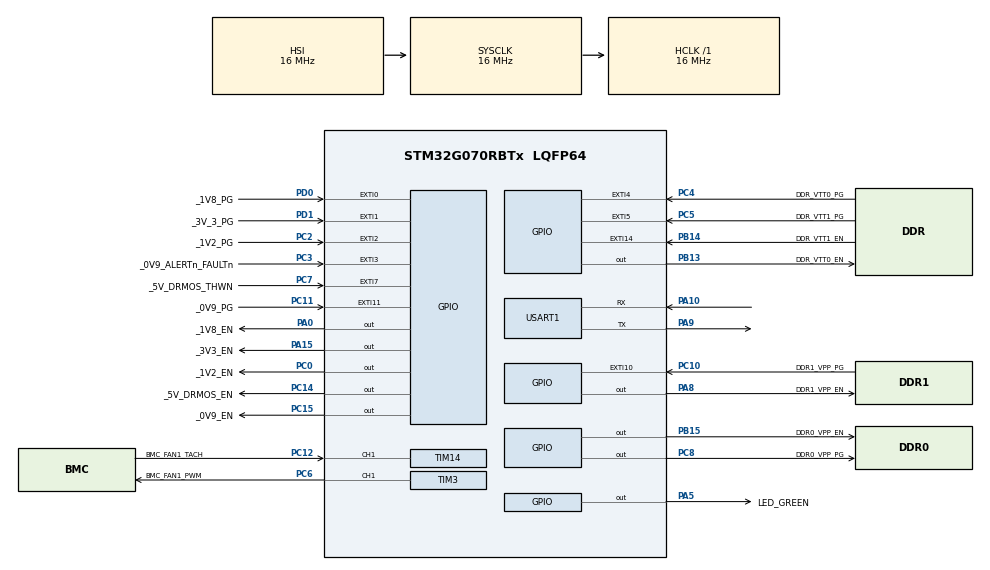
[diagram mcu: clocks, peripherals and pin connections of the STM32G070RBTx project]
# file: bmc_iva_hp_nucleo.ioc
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Mcu.Family=STM32G0
Mcu.Name=STM32G070RBTx
Mcu.Package=LQFP64
PA0.GPIO_Label=_1V8_EN
PA0.Signal=GPIO_Output
PA10.Mode=Asynchronous
PA10.Signal=USART1_RX
PA13.GPIO_Label=TMS
PA13.Mode=Serial_Wire
PA13.Signal=SYS_SWDIO
PA14-BOOT0.GPIO_Label=TCK
PA14-BOOT0.Mode=Serial_Wire
PA14-BOOT0.Signal=SYS_SWCLK
PA15.GPIO_Label=_3V3_EN
PA15.Signal=GPIO_Output
PA2.GPIO_PuPd=GPIO_PULLUP
PA2.Signal=USART2_TX
PA3.GPIO_PuPd=GPIO_PULLUP
PA3.Signal=USART2_RX
PA5.GPIO_Label=LED_GREEN
PA5.GPIO_Speed=GPIO_SPEED_FREQ_HIGH
PA5.Signal=GPIO_Output
PA8.GPIO_Label=DDR1_VPP_EN
PA8.Signal=GPIO_Output
PA9.Mode=Asynchronous
PA9.Signal=USART1_TX
PB13.GPIO_Label=DDR_VTT0_EN
PB13.Signal=GPIO_Output
PB14.GPIO_Label=DDR_VTT1_EN
PB14.Signal=GPXTI14
PB15.GPIO_Label=DDR0_VPP_EN
PB15.Signal=GPIO_Output
PC0.GPIO_Label=_1V2_EN
PC0.Signal=GPIO_Output
PC10.GPIO_Label=DDR1_VPP_PG
PC10.GPIO_ModeDefaultEXTI=GPIO_MODE_IT_RISING_FALLING
PC10.Signal=GPXTI10
PC11.GPIO_Label=_0V9_PG
PC11.GPIO_ModeDefaultEXTI=GPIO_MODE_IT_RISING_FALLING
PC11.Signal=GPXTI11
PC12.GPIO_Label=BMC_FAN1_TACH
PC12.Signal=S_TIM14_CH1
PC13.Mode=SYS_WakeUp1
PC13.Signal=SYS_WKUP2
PC14-OSC32_IN\ (PC14).GPIO_Label=_5V_DRMOS_EN
PC14-OSC32_IN\ (PC14).Signal=GPIO_Output
PC15-OSC32_OUT\ (PC15).GPIO_Label=_0V9_EN
PC15-OSC32_OUT\ (PC15).Signal=GPIO_Output
PC2.GPIO_Label=_1V2_PG
PC2.GPIO_ModeDefaultEXTI=GPIO_MODE_IT_RISING_FALLING
PC2.Signal=GPXTI2
PC3.GPIO_Label=_0V9_ALERTn_FAULTn
PC3.GPIO_ModeDefaultEXTI=GPIO_MODE_IT_RISING_FALLING
PC3.Signal=GPXTI3
PC4.GPIO_Label=DDR_VTT0_PG
PC4.GPIO_ModeDefaultEXTI=GPIO_MODE_IT_RISING_FALLING
PC4.Signal=GPXTI4
PC5.GPIO_Label=DDR_VTT1_PG
PC5.GPIO_ModeDefaultEXTI=GPIO_MODE_IT_RISING_FALLING
PC5.Signal=GPXTI5
PC6.GPIO_Label=BMC_FAN1_PWM
PC6.Signal=S_TIM3_CH1
PC7.GPIO_Label=_5V_DRMOS_THWN
PC7.GPIO_ModeDefaultEXTI=GPIO_MODE_IT_RISING_FALLING
PC7.Signal=GPXTI7
PC8.GPIO_Label=DDR0_VPP_PG
PC8.Signal=GPIO_Output
PD0.GPIO_Label=_1V8_PG
PD0.GPIO_ModeDefaultEXTI=GPIO_MODE_IT_RISING_FALLING
PD0.Signal=GPXTI0
PD1.GPIO_Label=_3V_3_PG
PD1.GPIO_ModeDefaultEXTI=GPIO_MODE_IT_RISING_FALLING
PD1.Signal=GPXTI1
PF0-OSC_IN\ (PF0).GPIO_Label=MCO
PF0-OSC_IN\ (PF0).Signal=RCC_OSC_IN
ProjectManager.HeapSize=0x200
ProjectManager.StackSize=0x400
ProjectManager.TargetToolchain=STM32CubeIDE
RCC.AHBFreq_Value=16000000
RCC.CortexFreq_Value=16000000
RCC.EXTERNAL_CLOCK_VALUE=12288000
RCC.HCLKFreq_Value=16000000
RCC.HSE_VALUE=8000000
RCC.HSI_VALUE=16000000
RCC.LSE_VALUE=32768
RCC.SYSCLKFreq_VALUE=16000000
RCC.VCOOutputFreq_Value=128000000
SH.S_TIM14_CH1.0=TIM14_CH1,Input_Capture1_from_TI1
SH.S_TIM3_CH1.0=TIM3_CH1,PWM Generation1 CH1
TIM14.Channel=TIM_CHANNEL_1
TIM14.Period=1000-1
TIM14.Prescaler=16000-1
TIM3.Channel-PWM\ Generation1\ CH1=TIM_CHANNEL_1
TIM3.Period=100-1
TIM3.Prescaler=160-1
USART1.VirtualMode-Asynchronous=VM_ASYNC
VP_SYS_VS_DBSignals.Mode=DisableDeadBatterySignals
VP_TIM14_VS_ClockSourceINT.Mode=Enable_Timer
VP_TIM3_VS_ClockSourceINT.Mode=Internal
board=NUCLEO-G070RB

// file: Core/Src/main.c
/* USER CODE BEGIN Header */
/**
  ******************************************************************************
  * @file           : main.c
  * @brief          : Main program body
  ******************************************************************************
  * @attention
  *
  * <h2><center>&copy; Copyright (c) 2021 STMicroelectronics.
  * All rights reserved.</center></h2>
  *
  * This software component is licensed by ST under BSD 3-Clause license,
  * the "License"; You may not use this file except in compliance with the
  * License. You may obtain a copy of the License at:
  *                        opensource.org/licenses/BSD-3-Clause
  *
  ******************************************************************************
  */
/* USER CODE END Header */
#include "main.h"

TIM_HandleTypeDef htim3;
TIM_HandleTypeDef htim14;

UART_HandleTypeDef huart1;

void SystemClock_Config(void);
static void MX_GPIO_Init(void);
static void MX_USART1_UART_Init(void);
static void MX_TIM3_Init(void);
static void MX_TIM14_Init(void);
/* USER CODE BEGIN PFP */
#ifdef __GNUC__
/* With GCC/RAISONANCE, small printf (option LD Linker->Libraries->Small printf
   set to 'Yes') calls __io_putchar() */
#define PUTCHAR_PROTOTYPE int __io_putchar(int ch)
#else
#define PUTCHAR_PROTOTYPE int fputc(int ch, FILE *f)
#endif /* __GNUC__ */
/**
  * @brief  Retargets the C library printf function to the USART.
  * @param  None
  * @retval None
  */
PUTCHAR_PROTOTYPE
/*int __io_putchar(int ch)*/
{
	HAL_UART_Transmit(&huart1, (uint8_t *)&ch, 1, 50);
	return ch;
}
/* USER CODE END PFP */

int main(void)
{

  /* MCU Configuration--------------------------------------------------------*/

  /* Reset of all peripherals, Initializes the Flash interface and the Systick. */
  HAL_Init();

  /* Configure the system clock */
  SystemClock_Config();

  /* Initialize all configured peripherals */
  MX_GPIO_Init();
  MX_USART1_UART_Init();
  MX_TIM3_Init();
  MX_TIM14_Init();
  /* USER CODE BEGIN 2 */
  start_debug_session();
  /* USER CODE END 2 */

  /* Infinite loop */
  /* USER CODE BEGIN WHILE */
  while (1)
  {

	  HAL_Delay(250);
	  HAL_GPIO_TogglePin(LED_GREEN_GPIO_Port, LED_GREEN_Pin);
    /* USER CODE END WHILE */

  }
}

void SystemClock_Config(void)
{
  RCC_OscInitTypeDef RCC_OscInitStruct = {0};
  RCC_ClkInitTypeDef RCC_ClkInitStruct = {0};
  RCC_PeriphCLKInitTypeDef PeriphClkInit = {0};

  /** Configure the main internal regulator output voltage
  */
  HAL_PWREx_ControlVoltageScaling(PWR_REGULATOR_VOLTAGE_SCALE1);
  /** Initializes the RCC Oscillators according to the specified parameters
  * in the RCC_OscInitTypeDef structure.
  */
  RCC_OscInitStruct.OscillatorType = RCC_OSCILLATORTYPE_HSI;
  RCC_OscInitStruct.HSIState = RCC_HSI_ON;
  RCC_OscInitStruct.HSIDiv = RCC_HSI_DIV1;
  RCC_OscInitStruct.HSICalibrationValue = RCC_HSICALIBRATION_DEFAULT;
  RCC_OscInitStruct.PLL.PLLState = RCC_PLL_NONE;
  if (HAL_RCC_OscConfig(&RCC_OscInitStruct) != HAL_OK)
  {
    Error_Handler();
  }
  /** Initializes the CPU, AHB and APB buses clocks
  */
  RCC_ClkInitStruct.ClockType = RCC_CLOCKTYPE_HCLK|RCC_CLOCKTYPE_SYSCLK
                              |RCC_CLOCKTYPE_PCLK1;
  RCC_ClkInitStruct.SYSCLKSource = RCC_SYSCLKSOURCE_HSI;
  RCC_ClkInitStruct.AHBCLKDivider = RCC_SYSCLK_DIV1;
  RCC_ClkInitStruct.APB1CLKDivider = RCC_HCLK_DIV1;

  if (HAL_RCC_ClockConfig(&RCC_ClkInitStruct, FLASH_LATENCY_0) != HAL_OK)
  {
    Error_Handler();
  }
  /** Initializes the peripherals clocks
  */
  PeriphClkInit.PeriphClockSelection = RCC_PERIPHCLK_USART1;
  PeriphClkInit.Usart1ClockSelection = RCC_USART1CLKSOURCE_PCLK1;
  if (HAL_RCCEx_PeriphCLKConfig(&PeriphClkInit) != HAL_OK)
  {
    Error_Handler();
  }
}

static void MX_TIM3_Init(void)
{

  TIM_ClockConfigTypeDef sClockSourceConfig = {0};
  TIM_MasterConfigTypeDef sMasterConfig = {0};
  TIM_OC_InitTypeDef sConfigOC = {0};

  htim3.Instance = TIM3;
  htim3.Init.Prescaler = 160-1;
  htim3.Init.CounterMode = TIM_COUNTERMODE_UP;
  htim3.Init.Period = 100-1;
  htim3.Init.ClockDivision = TIM_CLOCKDIVISION_DIV1;
  htim3.Init.AutoReloadPreload = TIM_AUTORELOAD_PRELOAD_DISABLE;
  if (HAL_TIM_Base_Init(&htim3) != HAL_OK)
  {
    Error_Handler();
  }
  sClockSourceConfig.ClockSource = TIM_CLOCKSOURCE_INTERNAL;
  if (HAL_TIM_ConfigClockSource(&htim3, &sClockSourceConfig) != HAL_OK)
  {
    Error_Handler();
  }
  if (HAL_TIM_PWM_Init(&htim3) != HAL_OK)
  {
    Error_Handler();
  }
  sMasterConfig.MasterOutputTrigger = TIM_TRGO_RESET;
  sMasterConfig.MasterSlaveMode = TIM_MASTERSLAVEMODE_DISABLE;
  if (HAL_TIMEx_MasterConfigSynchronization(&htim3, &sMasterConfig) != HAL_OK)
  {
    Error_Handler();
  }
  sConfigOC.OCMode = TIM_OCMODE_PWM1;
  sConfigOC.Pulse = 0;
  sConfigOC.OCPolarity = TIM_OCPOLARITY_HIGH;
  sConfigOC.OCFastMode = TIM_OCFAST_DISABLE;
  if (HAL_TIM_PWM_ConfigChannel(&htim3, &sConfigOC, TIM_CHANNEL_1) != HAL_OK)
  {
    Error_Handler();
  }
  HAL_TIM_MspPostInit(&htim3);

}

static void MX_TIM14_Init(void)
{

  TIM_IC_InitTypeDef sConfigIC = {0};

  htim14.Instance = TIM14;
  htim14.Init.Prescaler = 16000-1;
  htim14.Init.CounterMode = TIM_COUNTERMODE_UP;
  htim14.Init.Period = 1000-1;
  htim14.Init.ClockDivision = TIM_CLOCKDIVISION_DIV1;
  htim14.Init.AutoReloadPreload = TIM_AUTORELOAD_PRELOAD_DISABLE;
  if (HAL_TIM_Base_Init(&htim14) != HAL_OK)
  {
    Error_Handler();
  }
  if (HAL_TIM_IC_Init(&htim14) != HAL_OK)
  {
    Error_Handler();
  }
  sConfigIC.ICPolarity = TIM_INPUTCHANNELPOLARITY_RISING;
  sConfigIC.ICSelection = TIM_ICSELECTION_DIRECTTI;
  sConfigIC.ICPrescaler = TIM_ICPSC_DIV1;
  sConfigIC.ICFilter = 0;
  if (HAL_TIM_IC_ConfigChannel(&htim14, &sConfigIC, TIM_CHANNEL_1) != HAL_OK)
  {
    Error_Handler();
  }

}

static void MX_USART1_UART_Init(void)
{

  huart1.Instance = USART1;
  huart1.Init.BaudRate = 115200;
  huart1.Init.WordLength = UART_WORDLENGTH_8B;
  huart1.Init.StopBits = UART_STOPBITS_1;
  huart1.Init.Parity = UART_PARITY_NONE;
  huart1.Init.Mode = UART_MODE_TX_RX;
  huart1.Init.HwFlowCtl = UART_HWCONTROL_NONE;
  huart1.Init.OverSampling = UART_OVERSAMPLING_16;
  huart1.Init.OneBitSampling = UART_ONE_BIT_SAMPLE_DISABLE;
  huart1.Init.ClockPrescaler = UART_PRESCALER_DIV1;
  huart1.AdvancedInit.AdvFeatureInit = UART_ADVFEATURE_NO_INIT;
  if (HAL_UART_Init(&huart1) != HAL_OK)
  {
    Error_Handler();
  }
  if (HAL_UARTEx_SetTxFifoThreshold(&huart1, UART_TXFIFO_THRESHOLD_1_8) != HAL_OK)
  {
    Error_Handler();
  }
  if (HAL_UARTEx_SetRxFifoThreshold(&huart1, UART_RXFIFO_THRESHOLD_1_8) != HAL_OK)
  {
    Error_Handler();
  }
  if (HAL_UARTEx_DisableFifoMode(&huart1) != HAL_OK)
  {
    Error_Handler();
  }

}

static void MX_GPIO_Init(void)
{
  GPIO_InitTypeDef GPIO_InitStruct = {0};

  /* GPIO Ports Clock Enable */
  __HAL_RCC_GPIOC_CLK_ENABLE();
  __HAL_RCC_GPIOF_CLK_ENABLE();
  __HAL_RCC_GPIOA_CLK_ENABLE();
  __HAL_RCC_GPIOB_CLK_ENABLE();
  __HAL_RCC_GPIOD_CLK_ENABLE();

  /*Configure GPIO pin Output Level */
  HAL_GPIO_WritePin(GPIOC, _5V_DRMOS_EN_Pin|_0V9_EN_Pin|_1V2_EN_Pin|DDR0_VPP_PG_Pin, GPIO_PIN_RESET);

  /*Configure GPIO pin Output Level */
  HAL_GPIO_WritePin(GPIOA, _1V8_EN_Pin|LED_GREEN_Pin|DDR1_VPP_EN_Pin|_3V3_EN_Pin, GPIO_PIN_RESET);

  /*Configure GPIO pin Output Level */
  HAL_GPIO_WritePin(GPIOB, DDR_VTT0_EN_Pin|DDR0_VPP_EN_Pin, GPIO_PIN_RESET);

  /*Configure GPIO pins : _0V9_PG_Pin _1V2_PG_Pin _0V9_ALERTn_FAULTn_Pin DDR_VTT0_PG_Pin
                           DDR_VTT1_PG_Pin _5V_DRMOS_THWN_Pin DDR1_VPP_PG_Pin */
  GPIO_InitStruct.Pin = _0V9_PG_Pin|_1V2_PG_Pin|_0V9_ALERTn_FAULTn_Pin|DDR_VTT0_PG_Pin
                          |DDR_VTT1_PG_Pin|_5V_DRMOS_THWN_Pin|DDR1_VPP_PG_Pin;
  GPIO_InitStruct.Mode = GPIO_MODE_IT_RISING_FALLING;
  GPIO_InitStruct.Pull = GPIO_NOPULL;
  HAL_GPIO_Init(GPIOC, &GPIO_InitStruct);

  /*Configure GPIO pins : _5V_DRMOS_EN_Pin _0V9_EN_Pin _1V2_EN_Pin DDR0_VPP_PG_Pin */
  GPIO_InitStruct.Pin = _5V_DRMOS_EN_Pin|_0V9_EN_Pin|_1V2_EN_Pin|DDR0_VPP_PG_Pin;
  GPIO_InitStruct.Mode = GPIO_MODE_OUTPUT_PP;
  GPIO_InitStruct.Pull = GPIO_NOPULL;
  GPIO_InitStruct.Speed = GPIO_SPEED_FREQ_LOW;
  HAL_GPIO_Init(GPIOC, &GPIO_InitStruct);

  /*Configure GPIO pins : _1V8_EN_Pin DDR1_VPP_EN_Pin _3V3_EN_Pin */
  GPIO_InitStruct.Pin = _1V8_EN_Pin|DDR1_VPP_EN_Pin|_3V3_EN_Pin;
  GPIO_InitStruct.Mode = GPIO_MODE_OUTPUT_PP;
  GPIO_InitStruct.Pull = GPIO_NOPULL;
  GPIO_InitStruct.Speed = GPIO_SPEED_FREQ_LOW;
  HAL_GPIO_Init(GPIOA, &GPIO_InitStruct);

  /*Configure GPIO pins : PA2 PA3 */
  GPIO_InitStruct.Pin = GPIO_PIN_2|GPIO_PIN_3;
  GPIO_InitStruct.Mode = GPIO_MODE_AF_PP;
  GPIO_InitStruct.Pull = GPIO_PULLUP;
  GPIO_InitStruct.Speed = GPIO_SPEED_FREQ_LOW;
  GPIO_InitStruct.Alternate = GPIO_AF1_USART2;
  HAL_GPIO_Init(GPIOA, &GPIO_InitStruct);

  /*Configure GPIO pin : LED_GREEN_Pin */
  GPIO_InitStruct.Pin = LED_GREEN_Pin;
  GPIO_InitStruct.Mode = GPIO_MODE_OUTPUT_PP;
  GPIO_InitStruct.Pull = GPIO_NOPULL;
  GPIO_InitStruct.Speed = GPIO_SPEED_FREQ_HIGH;
  HAL_GPIO_Init(LED_GREEN_GPIO_Port, &GPIO_InitStruct);

  /*Configure GPIO pins : DDR_VTT0_EN_Pin DDR0_VPP_EN_Pin */
  GPIO_InitStruct.Pin = DDR_VTT0_EN_Pin|DDR0_VPP_EN_Pin;
  GPIO_InitStruct.Mode = GPIO_MODE_OUTPUT_PP;
  GPIO_InitStruct.Pull = GPIO_NOPULL;
  GPIO_InitStruct.Speed = GPIO_SPEED_FREQ_LOW;
  HAL_GPIO_Init(GPIOB, &GPIO_InitStruct);

  /*Configure GPIO pin : DDR_VTT1_EN_Pin */
  GPIO_InitStruct.Pin = DDR_VTT1_EN_Pin;
  GPIO_InitStruct.Mode = GPIO_MODE_IT_RISING;
  GPIO_InitStruct.Pull = GPIO_NOPULL;
  HAL_GPIO_Init(DDR_VTT1_EN_GPIO_Port, &GPIO_InitStruct);

  /*Configure GPIO pins : _1V8_PG_Pin _3V_3_PG_Pin */
  GPIO_InitStruct.Pin = _1V8_PG_Pin|_3V_3_PG_Pin;
  GPIO_InitStruct.Mode = GPIO_MODE_IT_RISING_FALLING;
  GPIO_InitStruct.Pull = GPIO_NOPULL;
  HAL_GPIO_Init(GPIOD, &GPIO_InitStruct);

}

void Error_Handler(void)
{
  __disable_irq();
  while (1)
  {
  }
}

/************************ (C) COPYRIGHT STMicroelectronics *****END OF FILE****/
